# ATSAMRH71F20B device description
Architecture: CORTEX-M7; Family: SAMRH; Series: SAMRH71
Registers are 32-bit, read-write, no defined reset value unless marked. A register's access mark holds for its fields unless they carry their own. Offsets are from the block's base; [hi:lo] are bit positions; {n}, {i} and the like mark numbered series; 'fields as' and 'values as' point back to an identical list.

## IP1553
Instances: IP1553 0x4003C000
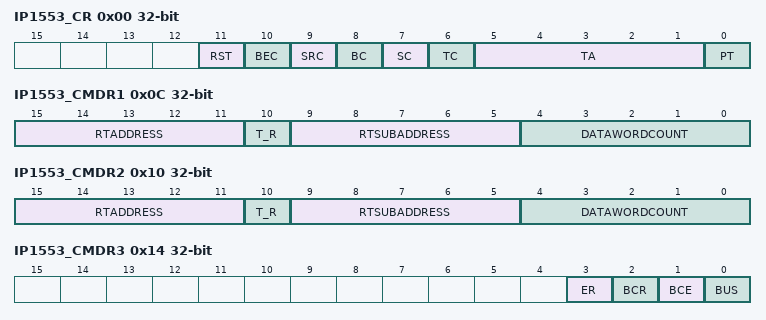
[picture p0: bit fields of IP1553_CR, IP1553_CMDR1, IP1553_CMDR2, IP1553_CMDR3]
0x00 IP1553_CR — Configuration Register
  [11] RST — Soft Reset
  [10] BEC — BCEnableCmd
  [9] SRC — SREQBitCmd
  [8] BC — BusyBitCmd
  [7] SC — SSBitCmd
  [6] TC — TRBitCmd
  [5:1] TA — TermAddressConf
  [0] PT — POTermConf
0x0C IP1553_CMDR1 wo — Command Register 1
  [15:11] RTADDRESS, [10] T_R, [9:5] RTSUBADDRESS, [4:0] DATAWORDCOUNT
0x10 IP1553_CMDR2 wo — Command Register 2
  [15:11] RTADDRESS
  [10] T_R — R/T
  [9:5] RTSUBADDRESS
  [4:0] DATAWORDCOUNT
0x14 IP1553_CMDR3 wo — Command Register 3
  [3] ER — data or command transfer
  [2] BCR — 1553 receiver
  [1] BCE — 1553 emitter
  [0] BUS — bus used
0x18 IP1553_BITR wo — BIT Register
  [15:0] TOBITWORD
0x1C IP1553_VWR wo — Vector Word Register
  [15:0] TOVECTORWORD
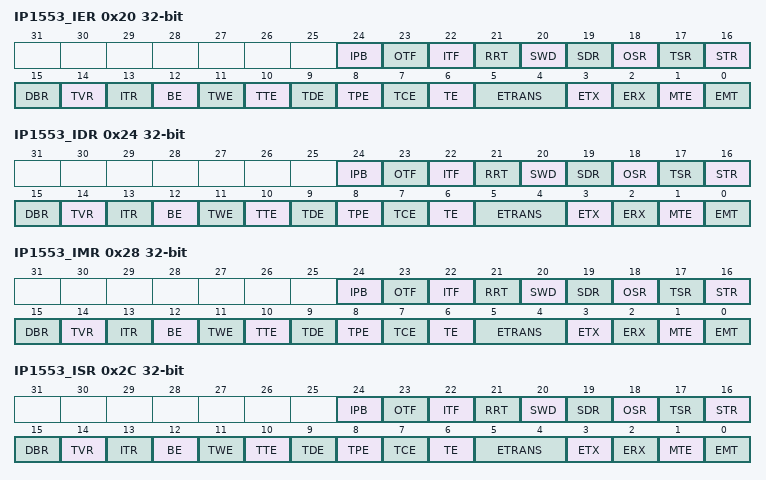
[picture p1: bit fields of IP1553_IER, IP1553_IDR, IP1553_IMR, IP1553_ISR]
0x20 IP1553_IER wo — IRQ Mask Enable Register
  [24] IPB — IPBusy
  [23] OTF — OvInhibitTermFlagReq
  [22] ITF — InhibitTermFlagReq
  [21] RRT — ResetRTReq
  [20] SWD — SyncWithoutDataReq
  [19] SDR — SyncWithDataReq
  [18] OSR — OvTranShutdownReq
  [17] TSR — TranShutdownReq
  [16] STR — InitSelfTestReq
  [15] DBR — DynamicBusContReq
  [14] TVR — TransVecWordReq
  [13] ITR — IllegalTransferReq
  [12] BE — BufIFErr
  [11] TWE — TransWordCounterErr
  [10] TTE — TransTimeOutErr
  [9] TDE — TransDataTypeErr
  [8] TPE — TransParityErr
  [7] TCE — TransCodingErr
  [6] TE — TransErr
  [5:4] ETRANS — EndTransfer
  [3] ETX — EndTransmission
  [2] ERX — End reception
  [1] MTE — MemTransferErr
  [0] EMT — EndMemTransfer
0x24 IP1553_IDR wo — IRQ Mask Disable Register
  fields as IP1553_IER
0x28 IP1553_IMR ro — IRQ Mask Register
  fields as IP1553_IER
0x2C IP1553_ISR ro — IRQ Status Register
  fields as IP1553_IER
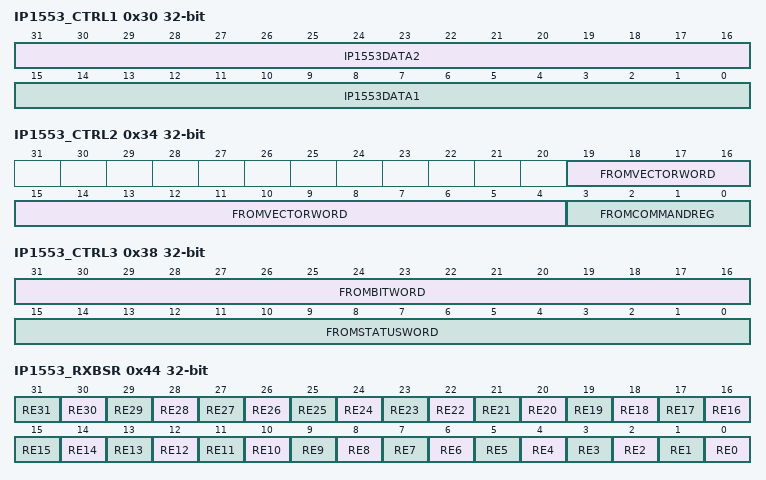
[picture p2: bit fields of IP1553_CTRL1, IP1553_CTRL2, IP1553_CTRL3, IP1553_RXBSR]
0x30 IP1553_CTRL1 ro — Control Register 1
  [31:16] IP1553DATA2 — IP1553 data value 2
  [15:0] IP1553DATA1 — IP1553 data value 1
0x34 IP1553_CTRL2 ro — Control Register 2
  [19:4] FROMVECTORWORD — from vector register
  [3:0] FROMCOMMANDREG — from command register
0x38 IP1553_CTRL3 ro — Control Register 3
  [31:16] FROMBITWORD — content of bit word register
  [15:0] FROMSTATUSWORD — content of status word register
0x3C IP1553_ARR — Address Register Read
  [31:0] REG_ADDR_APB_R — RX base address
0x40 IP1553_ARW — Address Register Write
  [31:0] REG_ADDR_APB_W — TX base address
0x44 IP1553_RXBSR — Rx Buffer Status Register
  [n] RE{n} (n=0..31) — Receive Buffer, {n} with x=[0-31]
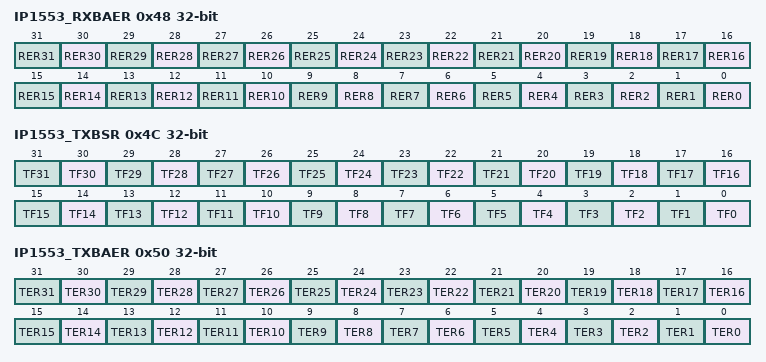
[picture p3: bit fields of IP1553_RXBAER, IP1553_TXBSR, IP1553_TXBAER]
0x48 IP1553_RXBAER — Rx Buffer Access Error Register
  [n] RER{n} (n=0..31) — Receive error {n}, x with x=[0-31]
0x4C IP1553_TXBSR — Tx Buffer Status Register
  [n] TF{n} (n=0..31) — Transmit buffer {n}, x with x=[0-31]
0x50 IP1553_TXBAER — Tx Buffer Access Error Register
  [n] TER{n} (n=0..31) — Transmit error {n}, x with x=[0-31]

## MCAN_RXBE — Rx Buffer Element
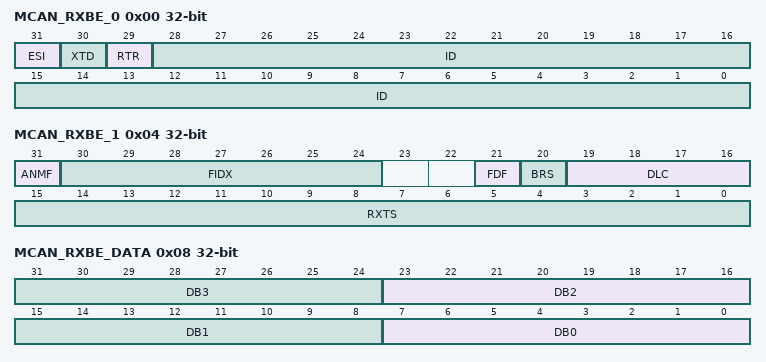
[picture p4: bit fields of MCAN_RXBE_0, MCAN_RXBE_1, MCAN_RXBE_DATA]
0x00 MCAN_RXBE_0 — Rx Buffer Element 0
  [31] ESI — Error State Indicator
  [30] XTD — Extended Identifier
  [29] RTR — Remote Transmission Request
  [28:0] ID — Identifier
0x04 MCAN_RXBE_1 — Rx Buffer Element 1
  [31] ANMF — Accepted Non-matching Frame
  [30:24] FIDX — Filter Index
  [21] FDF — FD Format
  [20] BRS — Bit Rate Switch
  [19:16] DLC — Data Length Code
  [15:0] RXTS — Rx Timestamp
0x08 MCAN_RXBE_DATA — Rx Buffer Element Data
  [8n+7:8n] DB{n} (n=0..3) — Data Byte {n}

## MCAN_RXF0E — Rx FIFO 0 Element
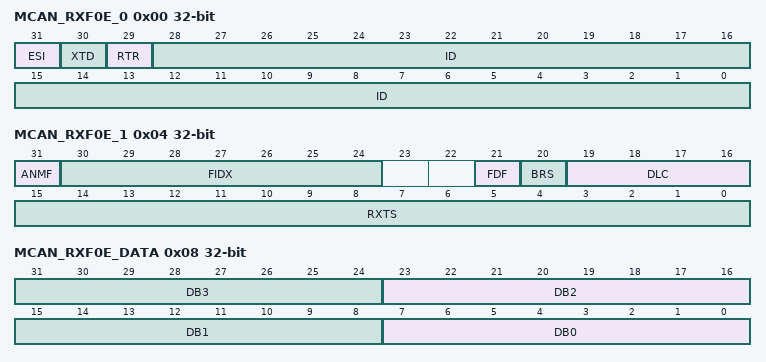
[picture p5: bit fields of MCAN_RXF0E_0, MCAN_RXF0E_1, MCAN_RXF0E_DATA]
0x00 MCAN_RXF0E_0 — Rx FIFO 0 Element 0
  [31] ESI — Error State Indicator
  [30] XTD — Extended Identifier
  [29] RTR — Remote Transmission Request
  [28:0] ID — Identifier
0x04 MCAN_RXF0E_1 — Rx FIFO 0 Element 1
  [31] ANMF — Accepted Non-matching Frame
  [30:24] FIDX — Filter Index
  [21] FDF — FD Format
  [20] BRS — Bit Rate Switch
  [19:16] DLC — Data Length Code
  [15:0] RXTS — Rx Timestamp
0x08 MCAN_RXF0E_DATA — Rx FIFO 0 Element Data
  [8n+7:8n] DB{n} (n=0..3) — Data Byte {n}
